# ATSAMD21G18A register map
Vendor: Microchip Technology Inc.; Series: SAMD21; File version: G
CPU: CM0+ r0p1, little endian, no MPU, no FPU, VTOR, 2 interrupt priority bits, 30 interrupts
Registers are 8-bit, read-write, reset 0x0 unless marked. A register's access mark holds for its fields unless they carry their own. Offsets are from the block's base; [hi:lo] are bit positions; {n}, {i} and the like mark numbered series; 'fields as' and 'values as' point back to an identical list.

## DMAC — Direct Memory Access Controller
Base 0x41004800; register names take the prefix DMAC_
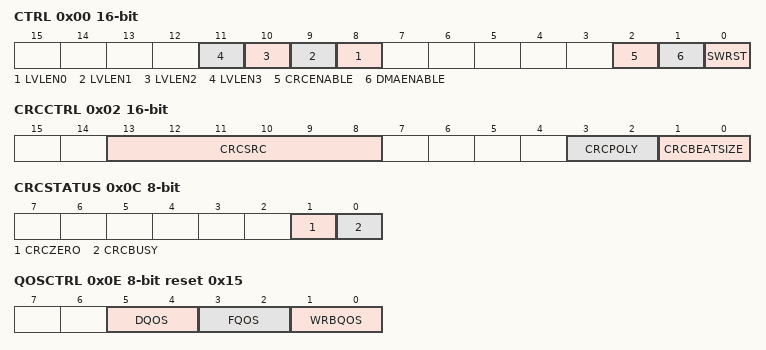
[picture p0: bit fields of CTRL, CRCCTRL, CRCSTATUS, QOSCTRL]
0x00 CTRL 16-bit — Control
  [n+8] LVLEN{n} (n=0..3) — Priority Level {n} Enable
  [2] CRCENABLE
  [1] DMAENABLE
  [0] SWRST — Software Reset
0x02 CRCCTRL 16-bit — CRC Control
  [13:8] CRCSRC — CRC Input Source
    0=NOACT (No action); 1=IO (I/O interface)
  [3:2] CRCPOLY — CRC Polynomial Type
    0=CRC16 (CRC-16 (CRC-CCITT)); 1=CRC32 (CRC32 (IEEE 802.3))
  [1:0] CRCBEATSIZE
    0=BYTE (Byte bus access); 1=HWORD (Half-word bus access); 2=WORD (Word bus access)
0x04 CRCDATAIN 32-bit — CRC Data Input
  [7:0] CRCDATAIN8 — CRC Data Input
  [15:0] CRCDATAIN16 — CRC Data Input
  [31:0] CRCDATAIN — CRC Data Input
0x08 CRCCHKSUM 32-bit — CRC Checksum
  [15:0] CRCCHKSUM16 — CRC Checksum
  [31:0] CRCCHKSUM32 — CRC Checksum
0x0C CRCSTATUS
  [1] CRCZERO ro
  [0] CRCBUSY write-1-clears — CRC Module Busy
0x0D DBGCTRL — Debug Control
  [0] DBGRUN — Debug Run
0x0E QOSCTRL reset 0x15 — QOS Control
  [all] fields
    0=DISABLE (Background (no sensitive operation)); 1=LOW (Sensitive Bandwidth); 2=MEDIUM (Sensitive Latency); 3=HIGH (Critical Latency)
  [5:4] DQOS — Data Transfer Quality of Service
  [3:2] FQOS — Fetch Quality of Service
  [1:0] WRBQOS — Write-Back Quality of Service
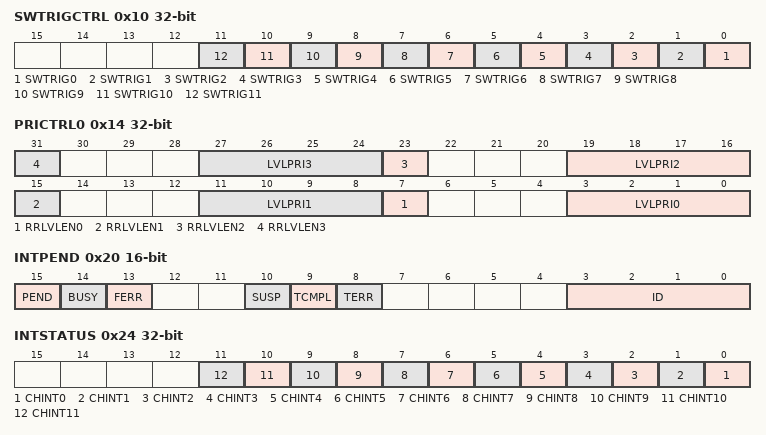
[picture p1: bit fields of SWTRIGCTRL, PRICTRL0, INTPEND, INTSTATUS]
0x10 SWTRIGCTRL 32-bit — Software Trigger Control
  [n] SWTRIG{n} (n=0..11) — Channel {n} Software Trigger
0x14 PRICTRL0 32-bit — Priority Control 0
  [8n+7] RRLVLEN{n} (n=0..3) — Level {n} Round-Robin Scheduling Enable
  [8n+3:8n] LVLPRI{n} (n=0..3) — Level {n} Channel Priority Number
0x20 INTPEND 16-bit — Interrupt Pending
  [15] PEND ro — Pending
  [14] BUSY ro
  [13] FERR ro — Fetch Error
  [10] SUSP write-1-clears — Channel Suspend
  [9] TCMPL write-1-clears — Transfer Complete
  [8] TERR write-1-clears — Transfer Error
  [3:0] ID — Channel ID
0x24 INTSTATUS 32-bit ro — Interrupt Status
  [n] CHINT{n} (n=0..11) — Channel {n} Pending Interrupt
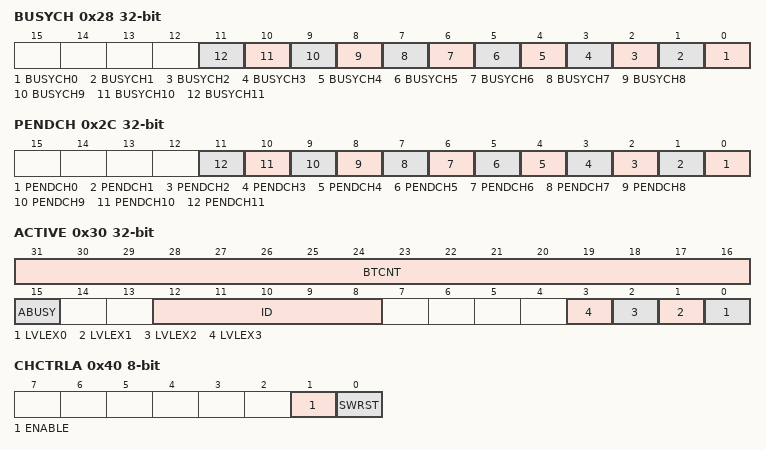
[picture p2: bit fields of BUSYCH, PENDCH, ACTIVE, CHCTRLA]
0x28 BUSYCH 32-bit ro — Busy Channels
  [n] BUSYCH{n} (n=0..11) — Busy Channel {n}
0x2C PENDCH 32-bit ro — Pending Channels
  [n] PENDCH{n} (n=0..11) — Pending Channel {n}
0x30 ACTIVE 32-bit ro — Active Channel and Levels
  [31:16] BTCNT — Active Channel Block Transfer Count
  [15] ABUSY — Active Channel Busy
  [12:8] ID — Active Channel ID
  [n] LVLEX{n} (n=0..3) — Level {n} Channel Trigger Request Executing
0x34 BASEADDR 32-bit — Descriptor Memory Section Base Address
  [31:0] BASEADDR — Descriptor Memory Base Address
0x38 WRBADDR 32-bit — Write-Back Memory Section Base Address
  [31:0] WRBADDR — Write-Back Memory Base Address
0x3F CHID — Channel ID
  [3:0] ID
0x40 CHCTRLA — Channel Control A
  [1] ENABLE — Channel Enable
  [0] SWRST — Channel Software Reset
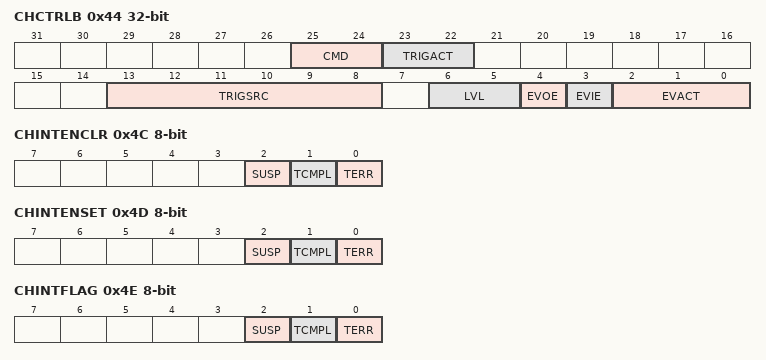
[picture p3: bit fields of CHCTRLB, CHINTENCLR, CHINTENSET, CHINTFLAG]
0x44 CHCTRLB 32-bit — Channel Control B
  [25:24] CMD — Software Command
    0=NOACT (No action); 1=SUSPEND (Channel suspend operation); 2=RESUME (Channel resume operation)
  [23:22] TRIGACT — Trigger Action
    0=BLOCK (One trigger required for each block transfer); 2=BEAT (One trigger required for each beat transfer); 3=TRANSACTION (One trigger required for each transaction)
  [13:8] TRIGSRC — Peripheral Trigger Source
    0=DISABLE (Only software/event triggers); 1=SERCOM0RX (SERCOM0 RX Trigger); 2=SERCOM0TX (SERCOM0 TX Trigger); 3=SERCOM1RX (SERCOM1 RX Trigger); 4=SERCOM1TX (SERCOM1 TX Trigger); 5=SERCOM2RX (SERCOM2 RX Trigger); 6=SERCOM2TX (SERCOM2 TX Trigger); 7=SERCOM3RX (SERCOM3 RX Trigger); 8=SERCOM3TX (SERCOM3 TX Trigger); 9=SERCOM4RX (SERCOM4 RX Trigger); 10=SERCOM4TX (SERCOM4 TX Trigger); 11=SERCOM5RX (SERCOM5 RX Trigger); 12=SERCOM5TX (SERCOM5 TX Trigger); 13=TCC0_OVF (TCC0 Overflow Trigger); {v}=TCC0_MC{v-14} (TCC0 Match/Compare {v-14} Trigger) (v=14..17); 18=TCC1_OVF (TCC1 Overflow Trigger); 19=TCC1_MC0 (TCC1 Match/Compare 0 Trigger); 20=TCC1_MC1 (TCC1 Match/Compare 1 Trigger); 21=TCC2_OVF (TCC2 Overflow Trigger); 22=TCC2_MC0 (TCC2 Match/Compare 0 Trigger); 23=TCC2_MC1 (TCC2 Match/Compare 1 Trigger); 24=TC3_OVF (TC3 Overflow Trigger); 25=TC3_MC0 (TC3 Match/Compare 0 Trigger); 26=TC3_MC1 (TC3 Match/Compare 1 Trigger); 27=TC4_OVF (TC4 Overflow Trigger); 28=TC4_MC0 (TC4 Match/Compare 0 Trigger); 29=TC4_MC1 (TC4 Match/Compare 1 Trigger); 30=TC5_OVF (TC5 Overflow Trigger); 31=TC5_MC0 (TC5 Match/Compare 0 Trigger); 32=TC5_MC1 (TC5 Match/Compare 1 Trigger); 33=TC6_OVF (TC6 Overflow Trigger); 34=TC6_MC0 (TC6 Match/Compare 0 Trigger); 35=TC6_MC1 (TC6 Match/Compare 1 Trigger); 36=TC7_OVF (TC7 Overflow Trigger); 37=TC7_MC0 (TC7 Match/Compare 0 Trigger); 38=TC7_MC1 (TC7 Match/Compare 1 Trigger); 39=ADC_RESRDY (ADC Result Ready Trigger); 40=DAC_EMPTY (DAC Empty Trigger); 41=I2S_RX_0 (I2S RX 0 Trigger); 42=I2S_RX_1 (I2S RX 1 Trigger); 43=I2S_TX_0 (I2S TX 0 Trigger); 44=I2S_TX_1 (I2S TX 1 Trigger); 45=OVF (TCC3 Overflow Trigger); 46=TCC3_MC0 (TCC3 Match/Compare 0 Trigger); 47=TCC3_MC1 (TCC3 Match/Compare 1 Trigger); 48=TCC3_MC2 (Match/Compare 2 Trigger); 49=TCC3_MC3 (Match/Compare 3 Trigger)
  [6:5] LVL — Channel Arbitration Level
    {v}=Channel Priority Level {v} (v=0..3)
  [4] EVOE — Channel Event Output Enable
  [3] EVIE — Channel Event Input Enable
  [2:0] EVACT — Event Input Action
    0=NOACT (No action); 1=TRIG (Transfer and periodic transfer trigger); 2=CTRIG (Conditional transfer trigger); 3=CBLOCK (Conditional block transfer); 4=SUSPEND (Channel suspend operation); 5=RESUME (Channel resume operation); 6=SSKIP (Skip next block suspend action)
0x4C CHINTENCLR — Channel Interrupt Enable Clear
  [2] SUSP — Channel Suspend Interrupt Enable
  [1] TCMPL — Transfer Complete Interrupt Enable
  [0] TERR — Transfer Error Interrupt Enable
0x4D CHINTENSET — Channel Interrupt Enable Set
  fields as CHINTENCLR
0x4E CHINTFLAG — Channel Interrupt Flag Status and Clear
  [2] SUSP write-1-clears — Channel Suspend
  [1] TCMPL write-1-clears — Transfer Complete
  [0] TERR write-1-clears — Transfer Error
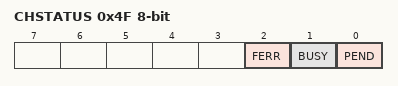
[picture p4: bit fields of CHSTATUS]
0x4F CHSTATUS ro — Channel Status
  [2] FERR — Fetch Error
  [1] BUSY — Channel Busy
  [0] PEND — Channel Pending

## Notices in the file
Copyright (c) 2018 Microchip Technology Inc.
SPDX-License-Identifier: Apache-2.0
Licensed under the Apache License, Version 2.0 (the "License");
you may not use this file except in compliance with the License.
You may obtain a copy of the License at
http://www.apache.org/licenses/LICENSE-2.0
Unless required by applicable law or agreed to in writing, software
distributed under the License is distributed on an "AS IS" BASIS,
WITHOUT WARRANTIES OR CONDITIONS OF ANY KIND, either express or implied.
See the License for the specific language governing permissions and
limitations under the License.
